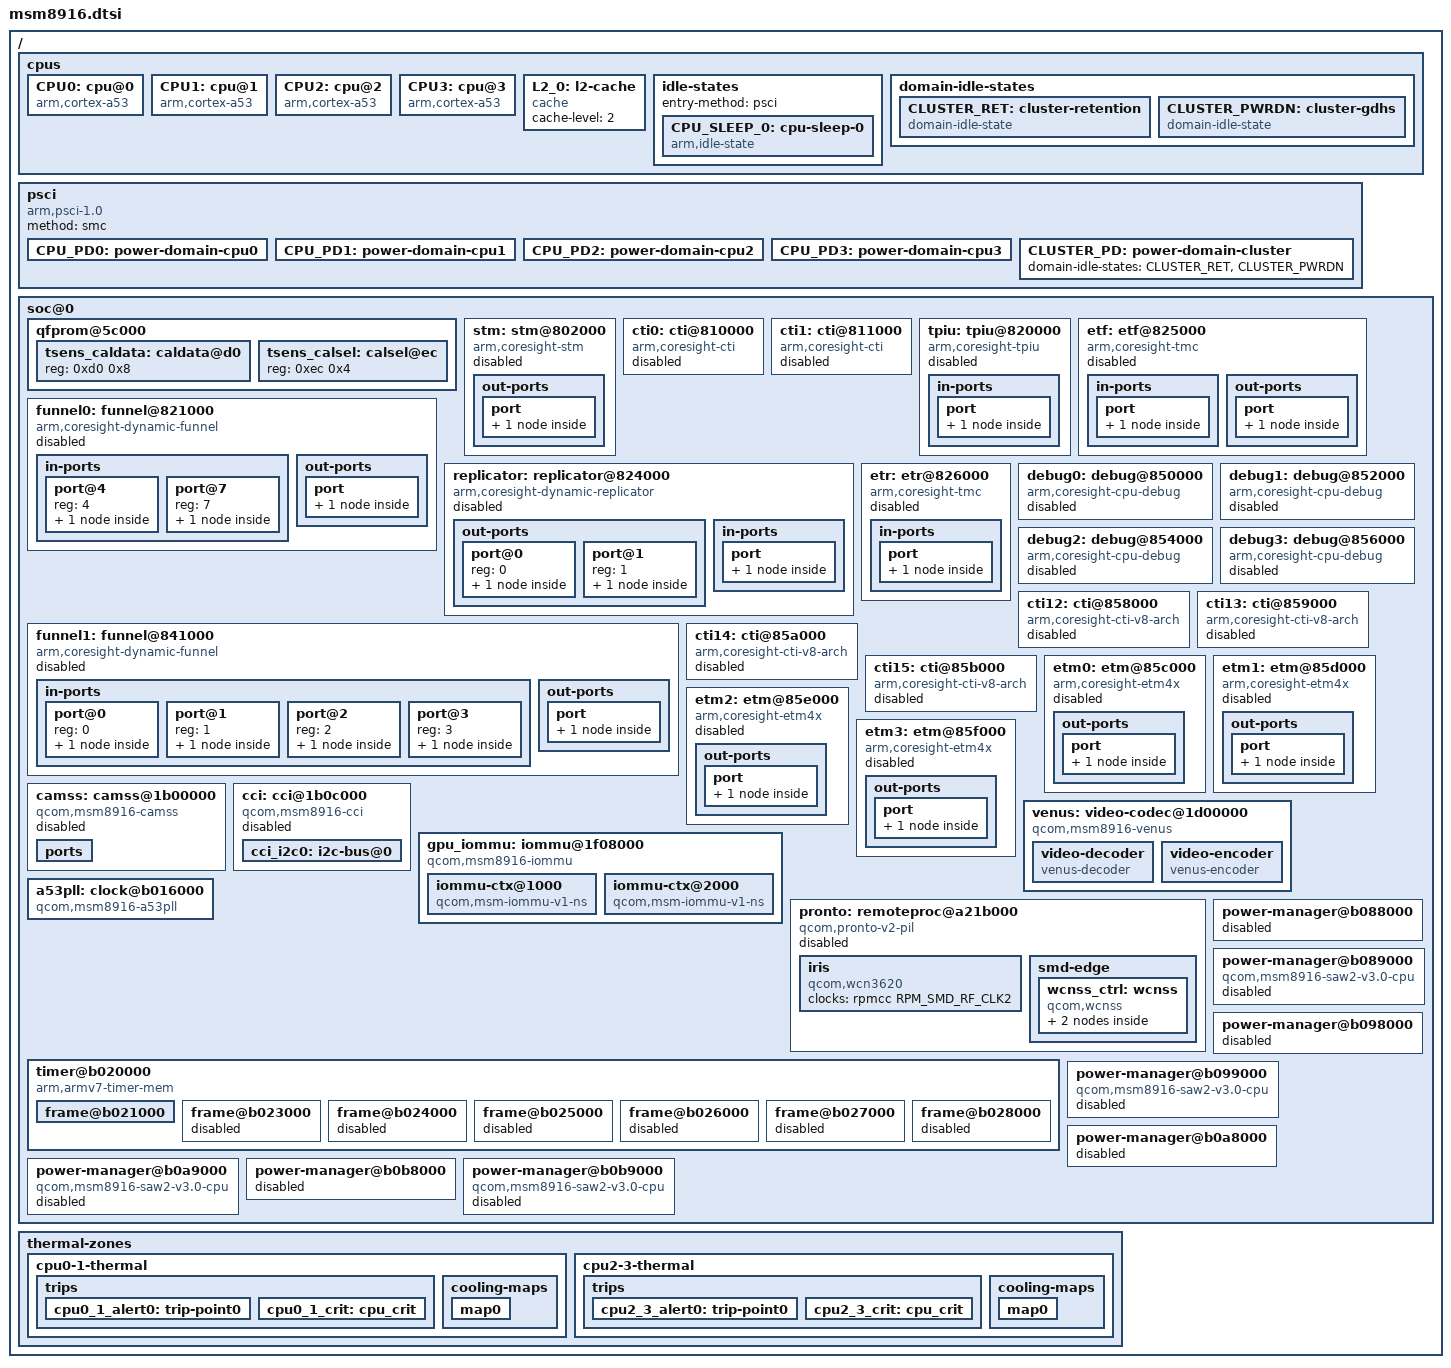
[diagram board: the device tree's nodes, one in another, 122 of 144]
// SPDX-License-Identifier: GPL-2.0-only
/*
 * Copyright (c) 2013-2015, The Linux Foundation. All rights reserved.
 */

#include <dt-bindings/arm/coresight-cti-dt.h>
#include <dt-bindings/clock/qcom,gcc-msm8916.h>
#include <dt-bindings/interconnect/qcom,msm8916.h>
#include <dt-bindings/reset/qcom,gcc-msm8916.h>

#include "msm8916-common.dtsi"

/ {
	cpus {
		#address-cells = <1>;
		#size-cells = <0>;

		CPU0: cpu@0 {
			device_type = "cpu";
			compatible = "arm,cortex-a53";
			reg = <0x0>;
			next-level-cache = <&L2_0>;
			enable-method = "psci";
			clocks = <&apcs>;
			operating-points-v2 = <&cpu_opp_table>;
			#cooling-cells = <2>;
			power-domains = <&CPU_PD0>;
			power-domain-names = "psci";
			qcom,acc = <&cpu0_acc>;
			qcom,saw = <&cpu0_saw>;
		};

		CPU1: cpu@1 {
			device_type = "cpu";
			compatible = "arm,cortex-a53";
			reg = <0x1>;
			next-level-cache = <&L2_0>;
			enable-method = "psci";
			clocks = <&apcs>;
			operating-points-v2 = <&cpu_opp_table>;
			#cooling-cells = <2>;
			power-domains = <&CPU_PD1>;
			power-domain-names = "psci";
			qcom,acc = <&cpu1_acc>;
			qcom,saw = <&cpu1_saw>;
		};

		CPU2: cpu@2 {
			device_type = "cpu";
			compatible = "arm,cortex-a53";
			reg = <0x2>;
			next-level-cache = <&L2_0>;
			enable-method = "psci";
			clocks = <&apcs>;
			operating-points-v2 = <&cpu_opp_table>;
			#cooling-cells = <2>;
			power-domains = <&CPU_PD2>;
			power-domain-names = "psci";
			qcom,acc = <&cpu2_acc>;
			qcom,saw = <&cpu2_saw>;
		};

		CPU3: cpu@3 {
			device_type = "cpu";
			compatible = "arm,cortex-a53";
			reg = <0x3>;
			next-level-cache = <&L2_0>;
			enable-method = "psci";
			clocks = <&apcs>;
			operating-points-v2 = <&cpu_opp_table>;
			#cooling-cells = <2>;
			power-domains = <&CPU_PD3>;
			power-domain-names = "psci";
			qcom,acc = <&cpu3_acc>;
			qcom,saw = <&cpu3_saw>;
		};

		L2_0: l2-cache {
			compatible = "cache";
			cache-level = <2>;
		};

		idle-states {
			entry-method = "psci";

			CPU_SLEEP_0: cpu-sleep-0 {
				compatible = "arm,idle-state";
				idle-state-name = "standalone-power-collapse";
				arm,psci-suspend-param = <0x40000002>;
				entry-latency-us = <130>;
				exit-latency-us = <150>;
				min-residency-us = <2000>;
				local-timer-stop;
			};
		};

		domain-idle-states {

			CLUSTER_RET: cluster-retention {
				compatible = "domain-idle-state";
				arm,psci-suspend-param = <0x41000012>;
				entry-latency-us = <500>;
				exit-latency-us = <500>;
				min-residency-us = <2000>;
			};

			CLUSTER_PWRDN: cluster-gdhs {
				compatible = "domain-idle-state";
				arm,psci-suspend-param = <0x41000032>;
				entry-latency-us = <2000>;
				exit-latency-us = <2000>;
				min-residency-us = <6000>;
			};
		};
	};

	psci {
		compatible = "arm,psci-1.0";
		method = "smc";

		CPU_PD0: power-domain-cpu0 {
			#power-domain-cells = <0>;
			power-domains = <&CLUSTER_PD>;
			domain-idle-states = <&CPU_SLEEP_0>;
		};

		CPU_PD1: power-domain-cpu1 {
			#power-domain-cells = <0>;
			power-domains = <&CLUSTER_PD>;
			domain-idle-states = <&CPU_SLEEP_0>;
		};

		CPU_PD2: power-domain-cpu2 {
			#power-domain-cells = <0>;
			power-domains = <&CLUSTER_PD>;
			domain-idle-states = <&CPU_SLEEP_0>;
		};

		CPU_PD3: power-domain-cpu3 {
			#power-domain-cells = <0>;
			power-domains = <&CLUSTER_PD>;
			domain-idle-states = <&CPU_SLEEP_0>;
		};

		CLUSTER_PD: power-domain-cluster {
			#power-domain-cells = <0>;
			domain-idle-states = <&CLUSTER_RET>, <&CLUSTER_PWRDN>;
		};
	};

	soc@0 {
		qfprom@5c000 {
			tsens_caldata: caldata@d0 {
				reg = <0xd0 0x8>;
			};
			tsens_calsel: calsel@ec {
				reg = <0xec 0x4>;
			};
		};

		stm: stm@802000 {
			compatible = "arm,coresight-stm", "arm,primecell";
			reg = <0x00802000 0x1000>,
			      <0x09280000 0x180000>;
			reg-names = "stm-base", "stm-stimulus-base";

			clocks = <&rpmcc RPM_QDSS_CLK>, <&rpmcc RPM_QDSS_A_CLK>;
			clock-names = "apb_pclk", "atclk";

			status = "disabled";

			out-ports {
				port {
					stm_out: endpoint {
						remote-endpoint = <&funnel0_in7>;
					};
				};
			};
		};

		/* System CTIs */
		/* CTI 0 - TMC connections */
		cti0: cti@810000 {
			compatible = "arm,coresight-cti", "arm,primecell";
			reg = <0x00810000 0x1000>;

			clocks = <&rpmcc RPM_QDSS_CLK>;
			clock-names = "apb_pclk";

			status = "disabled";
		};

		/* CTI 1 - TPIU connections */
		cti1: cti@811000 {
			compatible = "arm,coresight-cti", "arm,primecell";
			reg = <0x00811000 0x1000>;

			clocks = <&rpmcc RPM_QDSS_CLK>;
			clock-names = "apb_pclk";

			status = "disabled";
		};

		/* CTIs 2-11 - no information - not instantiated */

		tpiu: tpiu@820000 {
			compatible = "arm,coresight-tpiu", "arm,primecell";
			reg = <0x00820000 0x1000>;

			clocks = <&rpmcc RPM_QDSS_CLK>, <&rpmcc RPM_QDSS_A_CLK>;
			clock-names = "apb_pclk", "atclk";

			status = "disabled";

			in-ports {
				port {
					tpiu_in: endpoint {
						remote-endpoint = <&replicator_out1>;
					};
				};
			};
		};

		funnel0: funnel@821000 {
			compatible = "arm,coresight-dynamic-funnel", "arm,primecell";
			reg = <0x00821000 0x1000>;

			clocks = <&rpmcc RPM_QDSS_CLK>, <&rpmcc RPM_QDSS_A_CLK>;
			clock-names = "apb_pclk", "atclk";

			status = "disabled";

			in-ports {
				#address-cells = <1>;
				#size-cells = <0>;

				/*
				 * Not described input ports:
				 * 0 - connected to Resource and Power Manger CPU ETM
				 * 1 - not-connected
				 * 2 - connected to Modem CPU ETM
				 * 3 - not-connected
				 * 5 - not-connected
				 * 6 - connected trought funnel to Wireless CPU ETM
				 * 7 - connected to STM component
				 */

				port@4 {
					reg = <4>;
					funnel0_in4: endpoint {
						remote-endpoint = <&funnel1_out>;
					};
				};

				port@7 {
					reg = <7>;
					funnel0_in7: endpoint {
						remote-endpoint = <&stm_out>;
					};
				};
			};

			out-ports {
				port {
					funnel0_out: endpoint {
						remote-endpoint = <&etf_in>;
					};
				};
			};
		};

		replicator: replicator@824000 {
			compatible = "arm,coresight-dynamic-replicator", "arm,primecell";
			reg = <0x00824000 0x1000>;

			clocks = <&rpmcc RPM_QDSS_CLK>, <&rpmcc RPM_QDSS_A_CLK>;
			clock-names = "apb_pclk", "atclk";

			status = "disabled";

			out-ports {
				#address-cells = <1>;
				#size-cells = <0>;

				port@0 {
					reg = <0>;
					replicator_out0: endpoint {
						remote-endpoint = <&etr_in>;
					};
				};
				port@1 {
					reg = <1>;
					replicator_out1: endpoint {
						remote-endpoint = <&tpiu_in>;
					};
				};
			};

			in-ports {
				port {
					replicator_in: endpoint {
						remote-endpoint = <&etf_out>;
					};
				};
			};
		};

		etf: etf@825000 {
			compatible = "arm,coresight-tmc", "arm,primecell";
			reg = <0x00825000 0x1000>;

			clocks = <&rpmcc RPM_QDSS_CLK>, <&rpmcc RPM_QDSS_A_CLK>;
			clock-names = "apb_pclk", "atclk";

			status = "disabled";

			in-ports {
				port {
					etf_in: endpoint {
						remote-endpoint = <&funnel0_out>;
					};
				};
			};

			out-ports {
				port {
					etf_out: endpoint {
						remote-endpoint = <&replicator_in>;
					};
				};
			};
		};

		etr: etr@826000 {
			compatible = "arm,coresight-tmc", "arm,primecell";
			reg = <0x00826000 0x1000>;

			clocks = <&rpmcc RPM_QDSS_CLK>, <&rpmcc RPM_QDSS_A_CLK>;
			clock-names = "apb_pclk", "atclk";

			status = "disabled";

			in-ports {
				port {
					etr_in: endpoint {
						remote-endpoint = <&replicator_out0>;
					};
				};
			};
		};

		funnel1: funnel@841000 {	/* APSS funnel only 4 inputs are used */
			compatible = "arm,coresight-dynamic-funnel", "arm,primecell";
			reg = <0x00841000 0x1000>;

			clocks = <&rpmcc RPM_QDSS_CLK>, <&rpmcc RPM_QDSS_A_CLK>;
			clock-names = "apb_pclk", "atclk";

			status = "disabled";

			in-ports {
				#address-cells = <1>;
				#size-cells = <0>;

				port@0 {
					reg = <0>;
					funnel1_in0: endpoint {
						remote-endpoint = <&etm0_out>;
					};
				};
				port@1 {
					reg = <1>;
					funnel1_in1: endpoint {
						remote-endpoint = <&etm1_out>;
					};
				};
				port@2 {
					reg = <2>;
					funnel1_in2: endpoint {
						remote-endpoint = <&etm2_out>;
					};
				};
				port@3 {
					reg = <3>;
					funnel1_in3: endpoint {
						remote-endpoint = <&etm3_out>;
					};
				};
			};

			out-ports {
				port {
					funnel1_out: endpoint {
						remote-endpoint = <&funnel0_in4>;
					};
				};
			};
		};

		debug0: debug@850000 {
			compatible = "arm,coresight-cpu-debug", "arm,primecell";
			reg = <0x00850000 0x1000>;
			clocks = <&rpmcc RPM_QDSS_CLK>;
			clock-names = "apb_pclk";
			cpu = <&CPU0>;
			status = "disabled";
		};

		debug1: debug@852000 {
			compatible = "arm,coresight-cpu-debug", "arm,primecell";
			reg = <0x00852000 0x1000>;
			clocks = <&rpmcc RPM_QDSS_CLK>;
			clock-names = "apb_pclk";
			cpu = <&CPU1>;
			status = "disabled";
		};

		debug2: debug@854000 {
			compatible = "arm,coresight-cpu-debug", "arm,primecell";
			reg = <0x00854000 0x1000>;
			clocks = <&rpmcc RPM_QDSS_CLK>;
			clock-names = "apb_pclk";
			cpu = <&CPU2>;
			status = "disabled";
		};

		debug3: debug@856000 {
			compatible = "arm,coresight-cpu-debug", "arm,primecell";
			reg = <0x00856000 0x1000>;
			clocks = <&rpmcc RPM_QDSS_CLK>;
			clock-names = "apb_pclk";
			cpu = <&CPU3>;
			status = "disabled";
		};

		/* Core CTIs; CTIs 12-15 */
		/* CTI - CPU-0 */
		cti12: cti@858000 {
			compatible = "arm,coresight-cti-v8-arch", "arm,coresight-cti",
				     "arm,primecell";
			reg = <0x00858000 0x1000>;

			clocks = <&rpmcc RPM_QDSS_CLK>;
			clock-names = "apb_pclk";

			cpu = <&CPU0>;
			arm,cs-dev-assoc = <&etm0>;

			status = "disabled";
		};

		/* CTI - CPU-1 */
		cti13: cti@859000 {
			compatible = "arm,coresight-cti-v8-arch", "arm,coresight-cti",
				     "arm,primecell";
			reg = <0x00859000 0x1000>;

			clocks = <&rpmcc RPM_QDSS_CLK>;
			clock-names = "apb_pclk";

			cpu = <&CPU1>;
			arm,cs-dev-assoc = <&etm1>;

			status = "disabled";
		};

		/* CTI - CPU-2 */
		cti14: cti@85a000 {
			compatible = "arm,coresight-cti-v8-arch", "arm,coresight-cti",
				     "arm,primecell";
			reg = <0x0085a000 0x1000>;

			clocks = <&rpmcc RPM_QDSS_CLK>;
			clock-names = "apb_pclk";

			cpu = <&CPU2>;
			arm,cs-dev-assoc = <&etm2>;

			status = "disabled";
		};

		/* CTI - CPU-3 */
		cti15: cti@85b000 {
			compatible = "arm,coresight-cti-v8-arch", "arm,coresight-cti",
				     "arm,primecell";
			reg = <0x0085b000 0x1000>;

			clocks = <&rpmcc RPM_QDSS_CLK>;
			clock-names = "apb_pclk";

			cpu = <&CPU3>;
			arm,cs-dev-assoc = <&etm3>;

			status = "disabled";
		};

		etm0: etm@85c000 {
			compatible = "arm,coresight-etm4x", "arm,primecell";
			reg = <0x0085c000 0x1000>;

			clocks = <&rpmcc RPM_QDSS_CLK>, <&rpmcc RPM_QDSS_A_CLK>;
			clock-names = "apb_pclk", "atclk";
			arm,coresight-loses-context-with-cpu;

			cpu = <&CPU0>;

			status = "disabled";

			out-ports {
				port {
					etm0_out: endpoint {
						remote-endpoint = <&funnel1_in0>;
					};
				};
			};
		};

		etm1: etm@85d000 {
			compatible = "arm,coresight-etm4x", "arm,primecell";
			reg = <0x0085d000 0x1000>;

			clocks = <&rpmcc RPM_QDSS_CLK>, <&rpmcc RPM_QDSS_A_CLK>;
			clock-names = "apb_pclk", "atclk";
			arm,coresight-loses-context-with-cpu;

			cpu = <&CPU1>;

			status = "disabled";

			out-ports {
				port {
					etm1_out: endpoint {
						remote-endpoint = <&funnel1_in1>;
					};
				};
			};
		};

		etm2: etm@85e000 {
			compatible = "arm,coresight-etm4x", "arm,primecell";
			reg = <0x0085e000 0x1000>;

			clocks = <&rpmcc RPM_QDSS_CLK>, <&rpmcc RPM_QDSS_A_CLK>;
			clock-names = "apb_pclk", "atclk";
			arm,coresight-loses-context-with-cpu;

			cpu = <&CPU2>;

			status = "disabled";

			out-ports {
				port {
					etm2_out: endpoint {
						remote-endpoint = <&funnel1_in2>;
					};
				};
			};
		};

		etm3: etm@85f000 {
			compatible = "arm,coresight-etm4x", "arm,primecell";
			reg = <0x0085f000 0x1000>;

			clocks = <&rpmcc RPM_QDSS_CLK>, <&rpmcc RPM_QDSS_A_CLK>;
			clock-names = "apb_pclk", "atclk";
			arm,coresight-loses-context-with-cpu;

			cpu = <&CPU3>;

			status = "disabled";

			out-ports {
				port {
					etm3_out: endpoint {
						remote-endpoint = <&funnel1_in3>;
					};
				};
			};
		};

		camss: camss@1b00000 {
			compatible = "qcom,msm8916-camss";
			reg = <0x01b0ac00 0x200>,
				<0x01b00030 0x4>,
				<0x01b0b000 0x200>,
				<0x01b00038 0x4>,
				<0x01b08000 0x100>,
				<0x01b08400 0x100>,
				<0x01b0a000 0x500>,
				<0x01b00020 0x10>,
				<0x01b10000 0x1000>;
			reg-names = "csiphy0",
				"csiphy0_clk_mux",
				"csiphy1",
				"csiphy1_clk_mux",
				"csid0",
				"csid1",
				"ispif",
				"csi_clk_mux",
				"vfe0";
			interrupts = <GIC_SPI 78 IRQ_TYPE_EDGE_RISING>,
				<GIC_SPI 79 IRQ_TYPE_EDGE_RISING>,
				<GIC_SPI 51 IRQ_TYPE_EDGE_RISING>,
				<GIC_SPI 52 IRQ_TYPE_EDGE_RISING>,
				<GIC_SPI 55 IRQ_TYPE_EDGE_RISING>,
				<GIC_SPI 57 IRQ_TYPE_EDGE_RISING>;
			interrupt-names = "csiphy0",
				"csiphy1",
				"csid0",
				"csid1",
				"ispif",
				"vfe0";
			power-domains = <&gcc VFE_GDSC>;
			clocks = <&gcc GCC_CAMSS_TOP_AHB_CLK>,
				<&gcc GCC_CAMSS_ISPIF_AHB_CLK>,
				<&gcc GCC_CAMSS_CSI0PHYTIMER_CLK>,
				<&gcc GCC_CAMSS_CSI1PHYTIMER_CLK>,
				<&gcc GCC_CAMSS_CSI0_AHB_CLK>,
				<&gcc GCC_CAMSS_CSI0_CLK>,
				<&gcc GCC_CAMSS_CSI0PHY_CLK>,
				<&gcc GCC_CAMSS_CSI0PIX_CLK>,
				<&gcc GCC_CAMSS_CSI0RDI_CLK>,
				<&gcc GCC_CAMSS_CSI1_AHB_CLK>,
				<&gcc GCC_CAMSS_CSI1_CLK>,
				<&gcc GCC_CAMSS_CSI1PHY_CLK>,
				<&gcc GCC_CAMSS_CSI1PIX_CLK>,
				<&gcc GCC_CAMSS_CSI1RDI_CLK>,
				<&gcc GCC_CAMSS_AHB_CLK>,
				<&gcc GCC_CAMSS_VFE0_CLK>,
				<&gcc GCC_CAMSS_CSI_VFE0_CLK>,
				<&gcc GCC_CAMSS_VFE_AHB_CLK>,
				<&gcc GCC_CAMSS_VFE_AXI_CLK>;
			clock-names = "top_ahb",
				"ispif_ahb",
				"csiphy0_timer",
				"csiphy1_timer",
				"csi0_ahb",
				"csi0",
				"csi0_phy",
				"csi0_pix",
				"csi0_rdi",
				"csi1_ahb",
				"csi1",
				"csi1_phy",
				"csi1_pix",
				"csi1_rdi",
				"ahb",
				"vfe0",
				"csi_vfe0",
				"vfe_ahb",
				"vfe_axi";
			iommus = <&apps_iommu 3>;
			status = "disabled";
			ports {
				#address-cells = <1>;
				#size-cells = <0>;
			};
		};

		cci: cci@1b0c000 {
			compatible = "qcom,msm8916-cci";
			#address-cells = <1>;
			#size-cells = <0>;
			reg = <0x01b0c000 0x1000>;
			interrupts = <GIC_SPI 50 IRQ_TYPE_EDGE_RISING>;
			clocks = <&gcc GCC_CAMSS_TOP_AHB_CLK>,
				<&gcc GCC_CAMSS_CCI_AHB_CLK>,
				<&gcc GCC_CAMSS_CCI_CLK>,
				<&gcc GCC_CAMSS_AHB_CLK>;
			clock-names = "camss_top_ahb", "cci_ahb",
					  "cci", "camss_ahb";
			assigned-clocks = <&gcc GCC_CAMSS_CCI_AHB_CLK>,
					  <&gcc GCC_CAMSS_CCI_CLK>;
			assigned-clock-rates = <80000000>, <19200000>;
			pinctrl-0 = <&cci0_default>;
			pinctrl-names = "default";
			status = "disabled";

			cci_i2c0: i2c-bus@0 {
				reg = <0>;
				clock-frequency = <400000>;
				#address-cells = <1>;
				#size-cells = <0>;
			};
		};

		venus: video-codec@1d00000 {
			compatible = "qcom,msm8916-venus";
			reg = <0x01d00000 0xff000>;
			interrupts = <GIC_SPI 44 IRQ_TYPE_LEVEL_HIGH>;
			power-domains = <&gcc VENUS_GDSC>;
			clocks = <&gcc GCC_VENUS0_VCODEC0_CLK>,
				 <&gcc GCC_VENUS0_AHB_CLK>,
				 <&gcc GCC_VENUS0_AXI_CLK>;
			clock-names = "core", "iface", "bus";
			iommus = <&apps_iommu 5>;
			memory-region = <&venus_mem>;
			status = "okay";

			video-decoder {
				compatible = "venus-decoder";
			};

			video-encoder {
				compatible = "venus-encoder";
			};
		};

		gpu_iommu: iommu@1f08000 {
			#address-cells = <1>;
			#size-cells = <1>;
			#iommu-cells = <1>;
			compatible = "qcom,msm8916-iommu", "qcom,msm-iommu-v1";
			ranges = <0 0x01f08000 0x10000>;
			clocks = <&gcc GCC_SMMU_CFG_CLK>,
				 <&gcc GCC_GFX_TCU_CLK>;
			clock-names = "iface", "bus";
			qcom,iommu-secure-id = <18>;

			/* GFX3D_USER */
			iommu-ctx@1000 {
				compatible = "qcom,msm-iommu-v1-ns";
				reg = <0x1000 0x1000>;
				interrupts = <GIC_SPI 241 IRQ_TYPE_LEVEL_HIGH>;
			};

			/* GFX3D_PRIV */
			iommu-ctx@2000 {
				compatible = "qcom,msm-iommu-v1-ns";
				reg = <0x2000 0x1000>;
				interrupts = <GIC_SPI 242 IRQ_TYPE_LEVEL_HIGH>;
			};
		};

		pronto: remoteproc@a21b000 {
			compatible = "qcom,pronto-v2-pil", "qcom,pronto";
			reg = <0x0a204000 0x2000>, <0x0a202000 0x1000>, <0x0a21b000 0x3000>;
			reg-names = "ccu", "dxe", "pmu";

			memory-region = <&wcnss_mem>;

			interrupts-extended = <&intc GIC_SPI 149 IRQ_TYPE_EDGE_RISING>,
					      <&wcnss_smp2p_in 0 IRQ_TYPE_EDGE_RISING>,
					      <&wcnss_smp2p_in 1 IRQ_TYPE_EDGE_RISING>,
					      <&wcnss_smp2p_in 2 IRQ_TYPE_EDGE_RISING>,
					      <&wcnss_smp2p_in 3 IRQ_TYPE_EDGE_RISING>;
			interrupt-names = "wdog", "fatal", "ready", "handover", "stop-ack";

			power-domains = <&rpmpd MSM8916_VDDCX>,
					<&rpmpd MSM8916_VDDMX>;
			power-domain-names = "cx", "mx";

			qcom,smem-states = <&wcnss_smp2p_out 0>;
			qcom,smem-state-names = "stop";

			pinctrl-0 = <&wcnss_pin_a>;
			pinctrl-names = "default";

			status = "disabled";

			iris {
				compatible = "qcom,wcn3620";

				clocks = <&rpmcc RPM_SMD_RF_CLK2>;
				clock-names = "xo";
			};

			smd-edge {
				interrupts = <GIC_SPI 142 IRQ_TYPE_EDGE_RISING>;

				qcom,ipc = <&apcs 8 17>;
				qcom,smd-edge = <6>;
				qcom,remote-pid = <4>;

				label = "pronto";

				wcnss_ctrl: wcnss {
					compatible = "qcom,wcnss";
					qcom,smd-channels = "WCNSS_CTRL";

					qcom,mmio = <&pronto>;

					bluetooth {
						compatible = "qcom,wcnss-bt";
					};

					wifi {
						compatible = "qcom,wcnss-wlan";

						interrupts = <GIC_SPI 145 IRQ_TYPE_LEVEL_HIGH>,
							     <GIC_SPI 146 IRQ_TYPE_LEVEL_HIGH>;
						interrupt-names = "tx", "rx";

						qcom,smem-states = <&apps_smsm 10>, <&apps_smsm 9>;
						qcom,smem-state-names = "tx-enable", "tx-rings-empty";
					};
				};
			};
		};

		a53pll: clock@b016000 {
			compatible = "qcom,msm8916-a53pll";
			reg = <0x0b016000 0x40>;
			#clock-cells = <0>;
			clocks = <&xo_board>;
			clock-names = "xo";
		};

		timer@b020000 {
			#address-cells = <1>;
			#size-cells = <1>;
			ranges;
			compatible = "arm,armv7-timer-mem";
			reg = <0x0b020000 0x1000>;
			clock-frequency = <19200000>;

			frame@b021000 {
				frame-number = <0>;
				interrupts = <GIC_SPI 8 IRQ_TYPE_LEVEL_HIGH>,
					     <GIC_SPI 7 IRQ_TYPE_LEVEL_HIGH>;
				reg = <0x0b021000 0x1000>,
				      <0x0b022000 0x1000>;
			};

			frame@b023000 {
				frame-number = <1>;
				interrupts = <GIC_SPI 9 IRQ_TYPE_LEVEL_HIGH>;
				reg = <0x0b023000 0x1000>;
				status = "disabled";
			};

			frame@b024000 {
				frame-number = <2>;
				interrupts = <GIC_SPI 10 IRQ_TYPE_LEVEL_HIGH>;
				reg = <0x0b024000 0x1000>;
				status = "disabled";
			};

			frame@b025000 {
				frame-number = <3>;
				interrupts = <GIC_SPI 11 IRQ_TYPE_LEVEL_HIGH>;
				reg = <0x0b025000 0x1000>;
				status = "disabled";
			};

			frame@b026000 {
				frame-number = <4>;
				interrupts = <GIC_SPI 12 IRQ_TYPE_LEVEL_HIGH>;
				reg = <0x0b026000 0x1000>;
				status = "disabled";
			};

			frame@b027000 {
				frame-number = <5>;
				interrupts = <GIC_SPI 13 IRQ_TYPE_LEVEL_HIGH>;
				reg = <0x0b027000 0x1000>;
				status = "disabled";
			};

			frame@b028000 {
				frame-number = <6>;
				interrupts = <GIC_SPI 14 IRQ_TYPE_LEVEL_HIGH>;
				reg = <0x0b028000 0x1000>;
				status = "disabled";
			};
		};

		power-manager@b088000 {
			status = "reserved"; /* Controlled by PSCI firmware */
		};

		power-manager@b089000 {
			compatible = "qcom,msm8916-saw2-v3.0-cpu", "qcom,saw2";
			status = "reserved"; /* Controlled by PSCI firmware */
		};

		power-manager@b098000 {
			status = "reserved"; /* Controlled by PSCI firmware */
		};

		power-manager@b099000 {
			compatible = "qcom,msm8916-saw2-v3.0-cpu", "qcom,saw2";
			status = "reserved"; /* Controlled by PSCI firmware */
		};

		power-manager@b0a8000 {
			status = "reserved"; /* Controlled by PSCI firmware */
		};

		power-manager@b0a9000 {
			compatible = "qcom,msm8916-saw2-v3.0-cpu", "qcom,saw2";
			status = "reserved"; /* Controlled by PSCI firmware */
		};

		power-manager@b0b8000 {
			status = "reserved"; /* Controlled by PSCI firmware */
		};

		power-manager@b0b9000 {
			compatible = "qcom,msm8916-saw2-v3.0-cpu", "qcom,saw2";
			status = "reserved"; /* Controlled by PSCI firmware */
		};
	};

	thermal-zones {
		cpu0-1-thermal {
			polling-delay-passive = <250>;
			polling-delay = <1000>;

			thermal-sensors = <&tsens 5>;

			trips {
				cpu0_1_alert0: trip-point0 {
					temperature = <75000>;
					hysteresis = <2000>;
					type = "passive";
				};
				cpu0_1_crit: cpu_crit {
					temperature = <110000>;
					hysteresis = <2000>;
					type = "critical";
				};
			};

			cooling-maps {
				map0 {
					trip = <&cpu0_1_alert0>;
					cooling-device = <&CPU0 THERMAL_NO_LIMIT THERMAL_NO_LIMIT>,
							 <&CPU1 THERMAL_NO_LIMIT THERMAL_NO_LIMIT>,
							 <&CPU2 THERMAL_NO_LIMIT THERMAL_NO_LIMIT>,
							 <&CPU3 THERMAL_NO_LIMIT THERMAL_NO_LIMIT>;
				};
			};
		};

		cpu2-3-thermal {
			polling-delay-passive = <250>;
			polling-delay = <1000>;

			thermal-sensors = <&tsens 4>;

			trips {
				cpu2_3_alert0: trip-point0 {
					temperature = <75000>;
					hysteresis = <2000>;
					type = "passive";
				};
				cpu2_3_crit: cpu_crit {
					temperature = <110000>;
					hysteresis = <2000>;
					type = "critical";
				};
			};

			cooling-maps {
				map0 {
					trip = <&cpu2_3_alert0>;
					cooling-device = <&CPU0 THERMAL_NO_LIMIT THERMAL_NO_LIMIT>,
							 <&CPU1 THERMAL_NO_LIMIT THERMAL_NO_LIMIT>,
							 <&CPU2 THERMAL_NO_LIMIT THERMAL_NO_LIMIT>,
							 <&CPU3 THERMAL_NO_LIMIT THERMAL_NO_LIMIT>;
				};
			};
		};
	};
};
